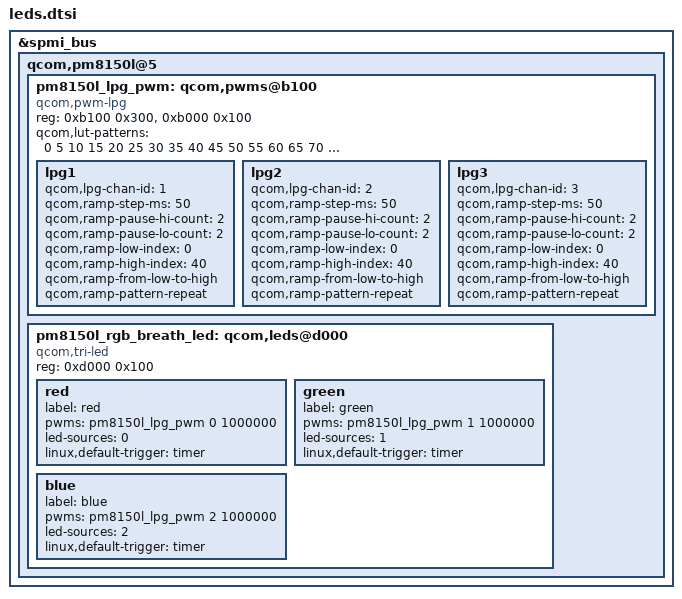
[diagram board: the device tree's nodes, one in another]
&spmi_bus {
    qcom,pm8150l@5 {
         pm8150l_lpg_pwm: qcom,pwms@b100 {
                compatible = "qcom,pwm-lpg";
		reg = <0xb100 0x300>, <0xb000 0x100>;
		reg-names = "lpg-base", "lut-base";
		#pwm-cells = <2>;
		qcom,lut-patterns = <0 5 10 15 20 25 30 35 40 45 50 55 60 65 70 75 80 85 90 95 100
				     95 90 85 80 75 70 65 60 55 50 45 40 35 30 25 20 15 10 5 0>;
		lpg1 {
			qcom,lpg-chan-id = <1>;
			qcom,ramp-step-ms = <50>;
			qcom,ramp-pause-hi-count = <2>;
			qcom,ramp-pause-lo-count = <2>;
			qcom,ramp-low-index = <0>;
			qcom,ramp-high-index = <40>;
			qcom,ramp-from-low-to-high;
			qcom,ramp-pattern-repeat;
		};

		lpg2 {
			qcom,lpg-chan-id = <2>;
			qcom,ramp-step-ms = <50>;
			qcom,ramp-pause-hi-count = <2>;
			qcom,ramp-pause-lo-count = <2>;
			qcom,ramp-low-index = <0>;
			qcom,ramp-high-index = <40>;
			qcom,ramp-from-low-to-high;
			qcom,ramp-pattern-repeat;
		};

		lpg3 {
			qcom,lpg-chan-id = <3>;
			qcom,ramp-step-ms = <50>;
			qcom,ramp-pause-hi-count = <2>;
			qcom,ramp-pause-lo-count = <2>;
			qcom,ramp-low-index = <0>;
			qcom,ramp-high-index = <40>;
			qcom,ramp-from-low-to-high;
			qcom,ramp-pattern-repeat;
		};
	};
        pm8150l_rgb_breath_led: qcom,leds@d000 {
		compatible = "qcom,tri-led";
		reg = <0xd000 0x100>;
		red {
			label = "red";
			pwms = <&pm8150l_lpg_pwm 0 1000000>;
			led-sources = <0>;
			linux,default-trigger = "timer";
		};
		green {
			label = "green";
			pwms = <&pm8150l_lpg_pwm 1 1000000>;
			led-sources = <1>;
			linux,default-trigger = "timer";
		};
		blue {
			label = "blue";
			pwms = <&pm8150l_lpg_pwm 2 1000000>;
			led-sources = <2>;
			linux,default-trigger = "timer";
		};
       };
    };	
};
